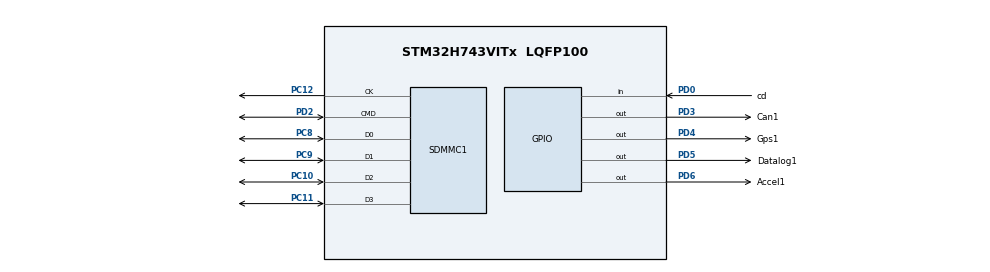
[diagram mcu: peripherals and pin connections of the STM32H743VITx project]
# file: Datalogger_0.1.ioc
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FATFS.BSP.number=1
FATFS0.BSP.STBoard=false
FATFS0.BSP.api=Unknown
FATFS0.BSP.instance=PD0
FATFS0.BSP.ip=GPIO
FATFS0.BSP.mode=Input
FATFS0.BSP.name=Detect_SDIO
FATFS0.BSP.solution=PD0
Mcu.Family=STM32H7
Mcu.Name=STM32H743VITx
Mcu.Package=LQFP100
NVIC.PriorityGroup=NVIC_PRIORITYGROUP_4
NVIC.SDMMC1_IRQn=true\:0\:0\:false\:false\:true\:true\:true\:true
PC10.Mode=SD_4_bits_Wide_bus
PC10.Signal=SDMMC1_D2
PC11.Mode=SD_4_bits_Wide_bus
PC11.Signal=SDMMC1_D3
PC12.Mode=SD_4_bits_Wide_bus
PC12.Signal=SDMMC1_CK
PC8.Mode=SD_4_bits_Wide_bus
PC8.Signal=SDMMC1_D0
PC9.Mode=SD_4_bits_Wide_bus
PC9.Signal=SDMMC1_D1
PD0.GPIO_Label=cd
PD0.Signal=GPIO_Input
PD2.Mode=SD_4_bits_Wide_bus
PD2.Signal=SDMMC1_CMD
PD3.GPIO_Label=Can1
PD3.GPIO_ModeDefaultOutputPP=GPIO_MODE_OUTPUT_OD
PD3.GPIO_PuPd=GPIO_NOPULL
PD3.PinState=GPIO_PIN_SET
PD3.Signal=GPIO_Output
PD4.GPIO_Label=Gps1
PD4.GPIO_ModeDefaultOutputPP=GPIO_MODE_OUTPUT_OD
PD4.GPIO_PuPd=GPIO_NOPULL
PD4.PinState=GPIO_PIN_SET
PD4.Signal=GPIO_Output
PD5.GPIO_Label=Datalog1
PD5.GPIO_ModeDefaultOutputPP=GPIO_MODE_OUTPUT_OD
PD5.GPIO_PuPd=GPIO_NOPULL
PD5.PinState=GPIO_PIN_SET
PD5.Signal=GPIO_Output
PD6.GPIO_Label=Accel1
PD6.GPIO_ModeDefaultOutputPP=GPIO_MODE_OUTPUT_OD
PD6.GPIO_PuPd=GPIO_NOPULL
PD6.GPIO_Speed=GPIO_SPEED_FREQ_LOW
PD6.PinState=GPIO_PIN_SET
PD6.Signal=GPIO_Output
ProjectManager.HeapSize=0x400
ProjectManager.StackSize=0x800
ProjectManager.TargetToolchain=STM32CubeIDE
RCC.ADCFreq_Value=129000000
RCC.APB1Freq_Value=64000000
RCC.APB2Freq_Value=64000000
RCC.APB3Freq_Value=64000000
RCC.APB4Freq_Value=64000000
RCC.CortexFreq_Value=64000000
RCC.DIVM1=4
RCC.DIVN1=9
RCC.HCLKFreq_Value=64000000
RCC.PLLFRACN=3072
RCC.SYSCLKFreq_VALUE=64000000
RCC.USBFreq_Value=75000000
VP_FATFS_VS_SDIO.Mode=SDIO
board=custom

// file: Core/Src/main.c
/* USER CODE BEGIN Header */
/**
  ******************************************************************************
  * @file           : main.c
  * @brief          : Main program body
  ******************************************************************************
  * @attention
  *
  * Copyright (c) 2023 STMicroelectronics.
  * All rights reserved.
  *
  * This software is licensed under terms that can be found in the LICENSE file
  * in the root directory of this software component.
  * If no LICENSE file comes with this software, it is provided AS-IS.
  *
  ******************************************************************************
  */
/* USER CODE END Header */
#include "main.h"
#include "fatfs.h"
#include "sdmmc.h"
#include "gpio.h"

/* USER CODE BEGIN PV */
HAL_StatusTypeDef status;
/* USER CODE END PV */

void SystemClock_Config(void);

/* USER CODE BEGIN 0 */
int num = 0;

/* USER CODE END 0 */

int main(void)
{
  /* USER CODE BEGIN 1 */
	FRESULT res; /* FatFs function common result code */
	uint32_t byteswritten, bytesread; /* File write/read counts */
	uint8_t wtext[] = "STM32 FATFS works great!"; /* File write buffer */
	uint8_t rtext[_MAX_SS];/* File read buffer */

  /* USER CODE END 1 */

  /* MCU Configuration--------------------------------------------------------*/

  /* Reset of all peripherals, Initializes the Flash interface and the Systick. */
  HAL_Init();

  /* Configure the system clock */
  SystemClock_Config();

  /* Initialize all configured peripherals */
  MX_GPIO_Init();
  MX_SDMMC1_SD_Init();
  MX_FATFS_Init();
  /* USER CODE BEGIN 2 */

  HAL_GPIO_WritePin(GPIOD, Gps1_Pin, GPIO_PIN_RESET);

  /* USER CODE END 2 */

  /* Infinite loop */
  while (1)
  {

  }
}

void SystemClock_Config(void)
{
  RCC_OscInitTypeDef RCC_OscInitStruct = {0};
  RCC_ClkInitTypeDef RCC_ClkInitStruct = {0};

  /** Supply configuration update enable
  */
  HAL_PWREx_ConfigSupply(PWR_LDO_SUPPLY);

  /** Configure the main internal regulator output voltage
  */
  __HAL_PWR_VOLTAGESCALING_CONFIG(PWR_REGULATOR_VOLTAGE_SCALE3);

  while(!__HAL_PWR_GET_FLAG(PWR_FLAG_VOSRDY)) {}

  /** Initializes the RCC Oscillators according to the specified parameters
  * in the RCC_OscInitTypeDef structure.
  */
  RCC_OscInitStruct.OscillatorType = RCC_OSCILLATORTYPE_HSI;
  RCC_OscInitStruct.HSIState = RCC_HSI_DIV1;
  RCC_OscInitStruct.HSICalibrationValue = RCC_HSICALIBRATION_DEFAULT;
  RCC_OscInitStruct.PLL.PLLState = RCC_PLL_ON;
  RCC_OscInitStruct.PLL.PLLSource = RCC_PLLSOURCE_HSI;
  RCC_OscInitStruct.PLL.PLLM = 4;
  RCC_OscInitStruct.PLL.PLLN = 9;
  RCC_OscInitStruct.PLL.PLLP = 2;
  RCC_OscInitStruct.PLL.PLLQ = 2;
  RCC_OscInitStruct.PLL.PLLR = 2;
  RCC_OscInitStruct.PLL.PLLRGE = RCC_PLL1VCIRANGE_3;
  RCC_OscInitStruct.PLL.PLLVCOSEL = RCC_PLL1VCOMEDIUM;
  RCC_OscInitStruct.PLL.PLLFRACN = 3072;
  if (HAL_RCC_OscConfig(&RCC_OscInitStruct) != HAL_OK)
  {
    Error_Handler();
  }

  /** Initializes the CPU, AHB and APB buses clocks
  */
  RCC_ClkInitStruct.ClockType = RCC_CLOCKTYPE_HCLK|RCC_CLOCKTYPE_SYSCLK
                              |RCC_CLOCKTYPE_PCLK1|RCC_CLOCKTYPE_PCLK2
                              |RCC_CLOCKTYPE_D3PCLK1|RCC_CLOCKTYPE_D1PCLK1;
  RCC_ClkInitStruct.SYSCLKSource = RCC_SYSCLKSOURCE_HSI;
  RCC_ClkInitStruct.SYSCLKDivider = RCC_SYSCLK_DIV1;
  RCC_ClkInitStruct.AHBCLKDivider = RCC_HCLK_DIV1;
  RCC_ClkInitStruct.APB3CLKDivider = RCC_APB3_DIV1;
  RCC_ClkInitStruct.APB1CLKDivider = RCC_APB1_DIV1;
  RCC_ClkInitStruct.APB2CLKDivider = RCC_APB2_DIV1;
  RCC_ClkInitStruct.APB4CLKDivider = RCC_APB4_DIV1;

  if (HAL_RCC_ClockConfig(&RCC_ClkInitStruct, FLASH_LATENCY_1) != HAL_OK)
  {
    Error_Handler();
  }
}

void Error_Handler(void)
{
  /* USER CODE BEGIN Error_Handler_Debug */
  /* User can add his own implementation to report the HAL error return state */
  __disable_irq();
  while (1)
  {
	// I wanted that wayyyyyyy
  }
  /* USER CODE END Error_Handler_Debug */
}
